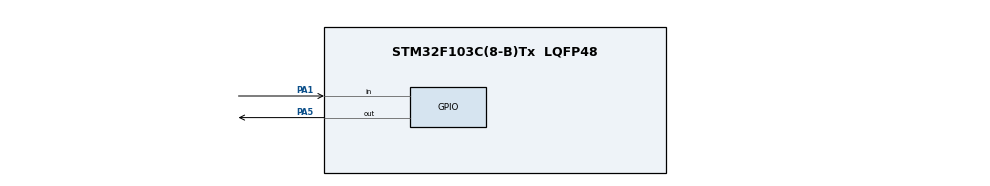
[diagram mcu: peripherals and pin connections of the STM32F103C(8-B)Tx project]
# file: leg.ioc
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Mcu.Family=STM32F1
Mcu.Name=STM32F103C(8-B)Tx
Mcu.Package=LQFP48
NVIC.PriorityGroup=NVIC_PRIORITYGROUP_4
PA1.GPIO_PuPd=GPIO_PULLUP
PA1.Signal=GPIO_Input
PA11.Signal=S_TIM1_CH4
PA13.Mode=JTAG_4_pins
PA13.Signal=SYS_JTMS-SWDIO
PA14.Mode=JTAG_4_pins
PA14.Signal=SYS_JTCK-SWCLK
PA15.Mode=JTAG_4_pins
PA15.Signal=SYS_JTDI
PA5.GPIO_Speed=GPIO_SPEED_FREQ_MEDIUM
PA5.Signal=GPIO_Output
PA5.Stacked=true
PB3.Mode=JTAG_4_pins
PB3.Signal=SYS_JTDO-TRACESWO
PD0-OSC_IN.Mode=HSE-External-Oscillator
PD0-OSC_IN.Signal=RCC_OSC_IN
PD1-OSC_OUT.Mode=HSE-External-Oscillator
PD1-OSC_OUT.Signal=RCC_OSC_OUT
ProjectManager.HeapSize=0x200
ProjectManager.StackSize=0x400
ProjectManager.TargetToolchain=STM32CubeIDE
RCC.AHBFreq_Value=72000000
RCC.APB1CLKDivider=RCC_HCLK_DIV2
RCC.APB1Freq_Value=36000000
RCC.APB1TimFreq_Value=72000000
RCC.APB2Freq_Value=72000000
RCC.APB2TimFreq_Value=72000000
RCC.HCLKFreq_Value=72000000
RCC.PLLMUL=RCC_PLL_MUL9
RCC.PLLSourceVirtual=RCC_PLLSOURCE_HSE
RCC.SYSCLKFreq_VALUE=72000000
RCC.SYSCLKSource=RCC_SYSCLKSOURCE_PLLCLK
RCC.USBFreq_Value=72000000
SH.S_TIM1_CH4.0=TIM1_CH4
board=custom

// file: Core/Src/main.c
/* USER CODE BEGIN Header */

/* USER CODE BEGIN PV */
#define LED4_ON() LL_GPIO_SetOutputPin(GPIOA, LL_GPIO_PIN_5)
#define LED4_OFF() LL_GPIO_ResetOutputPin(GPIOA, LL_GPIO_PIN_5)
#define TIM_CCER_CC3NE                                           ((uint16_t)0x0400)
#define TIMER_PRESCALER                                          720
#define EXT_TIM_PULSE                                            150
#define TIM_PULSE                                                50
//#define LED8_ON() LL_GPIO_SetOutputPin(GPIOB, LL_GPIO_PIN_1)
//#define LED8_OFF() LL_GPIO_ResetOutputPin(GPIOB, LL_GPIO_PIN_1)
/**
  ******************************************************************************
  * @file           : main.c
  * @brief          : Main program body
  ******************************************************************************
  * @attention
  *
  * <h2><center>&copy; Copyright (c) 2021 STMicroelectronics.
  * All rights reserved.</center></h2>
  *
  * This software component is licensed by ST under BSD 3-Clause license,
  * the "License"; You may not use this file except in compliance with the
  * License. You may obtain a copy of the License at:
  *                        opensource.org/licenses/BSD-3-Clause
  *
  ******************************************************************************
  */
/* USER CODE END Header */
#include "main.h"

/* USER CODE BEGIN PV */
#define LED4_ON() LL_GPIO_SetOutputPin(GPIOA, LL_GPIO_PIN_5)
#define LED4_OFF() LL_GPIO_ResetOutputPin(GPIOA, LL_GPIO_PIN_5)
//#define LED8_ON() LL_GPIO_SetOutputPin(GPIOB, LL_GPIO_PIN_1)
//#define LED8_OFF() LL_GPIO_ResetOutputPin(GPIOB, LL_GPIO_PIN_1)
/**
  ******************************************************************************
  * @file           : main.c
  * @brief          : Main program body
  ******************************************************************************
  * @attention
  *
  * <h2><center>&copy; Copyright (c) 2021 STMicroelectronics.
  * All rights reserved.</center></h2>
  *
  * This software component is licensed by ST under BSD 3-Clause license,
  * the "License"; You may not use this file except in compliance with the
  * License. You may obtain a copy of the License at:
  *                        opensource.org/licenses/BSD-3-Clause
  *
  ******************************************************************************
  */
/* USER CODE END Header */
/* Includes ------------------------------------------------------------------*/
#include "main.h"

/* Private includes ----------------------------------------------------------*/
/* USER CODE BEGIN Includes */

/* USER CODE END Includes */

/* Private typedef -----------------------------------------------------------*/
/* USER CODE BEGIN PTD */

/* USER CODE END PTD */

/* Private define ------------------------------------------------------------*/
/* USER CODE BEGIN PD */
/* USER CODE END PD */

/* Private macro -------------------------------------------------------------*/
/* USER CODE BEGIN PM */

/* USER CODE END PM */

/* Private variables ---------------------------------------------------------*/

/* USER CODE BEGIN PV */
#define LED4_ON() LL_GPIO_SetOutputPin(GPIOA, LL_GPIO_PIN_5)
#define LED4_OFF() LL_GPIO_ResetOutputPin(GPIOA, LL_GPIO_PIN_5)
//#define LED8_ON() LL_GPIO_SetOutputPin(GPIOB, LL_GPIO_PIN_1)
//#define LED8_OFF() LL_GPIO_ResetOutputPin(GPIOB, LL_GPIO_PIN_1)
/**
  ******************************************************************************
  * @file           : main.c
  * @brief          : Main program body
  ******************************************************************************
  * @attention
  *
  * <h2><center>&copy; Copyright (c) 2021 STMicroelectronics.
  * All rights reserved.</center></h2>
  *
  * This software component is licensed by ST under BSD 3-Clause license,
  * the "License"; You may not use this file except in compliance with the
  * License. You may obtain a copy of the License at:
  *                        opensource.org/licenses/BSD-3-Clause
  *
  ******************************************************************************
  */
/* USER CODE END Header */
/* Includes ------------------------------------------------------------------*/
#include "main.h"

/* Private includes ----------------------------------------------------------*/
/* USER CODE BEGIN Includes */

/* USER CODE END Includes */

/* Private typedef -----------------------------------------------------------*/
/* USER CODE BEGIN PTD */

/* USER CODE END PTD */

/* Private define ------------------------------------------------------------*/
/* USER CODE BEGIN PD */
/* USER CODE END PD */

/* Private macro -------------------------------------------------------------*/
/* USER CODE BEGIN PM */

/* USER CODE END PM */

/* Private variables ---------------------------------------------------------*/

/* USER CODE BEGIN PV */

/* USER CODE END PV */

void SystemClock_Config(void);
static void MX_GPIO_Init(void);

int main(void)
{

  /* MCU Configuration--------------------------------------------------------*/

  /* Reset of all peripherals, Initializes the Flash interface and the Systick. */

  LL_APB2_GRP1_EnableClock(LL_APB2_GRP1_PERIPH_AFIO);
  LL_APB1_GRP1_EnableClock(LL_APB1_GRP1_PERIPH_PWR);

  NVIC_SetPriorityGrouping(NVIC_PRIORITYGROUP_4);

  /* System interrupt init*/
  /* SysTick_IRQn interrupt configuration */
  NVIC_SetPriority(SysTick_IRQn, NVIC_EncodePriority(NVIC_GetPriorityGrouping(),15, 0));

  /** NONJTRST: Full SWJ (JTAG-DP + SW-DP) but without NJTRST
  */
  LL_GPIO_AF_Remap_SWJ_NONJTRST();

  /* Configure the system clock */
  SystemClock_Config();

  /* Initialize all configured peripherals */
  MX_GPIO_Init();
  /* USER CODE BEGIN 2 */
  uint16_t previousState;
  GPIO_InitTypeDef port;
  TIM_TimeBaseInitTypeDef timer;
  TIM_OCInitTypeDef timerPWM;
  uint16_t buttonPreviousState;

  /* USER CODE END 2 */

  /* Infinite loop */
  while (1)
  {

    /* USER CODE BEGIN 3 */
	  LED4_OFF();
	  LL_mDelay(100);
	  LED4_ON();
	  LL_mDelay(200);
	  TIM_OCStructInit(&timerPWM);
	  timerPWM.TIM_Pulse = 50;
	  timerPWM.TIM_OCMode = TIM_OCMode_PWM1;
	  timerPWM.TIM_OutputState = TIM_OutputState_Enable;
	  TIM_OC1Init(TIM4, &timerPWM);
  }
  /* USER CODE END 3 */
}

void SystemClock_Config(void)
{
  LL_FLASH_SetLatency(LL_FLASH_LATENCY_2);
  while(LL_FLASH_GetLatency()!= LL_FLASH_LATENCY_2)
  {
  }
  LL_RCC_HSE_Enable();

   /* Wait till HSE is ready */
  while(LL_RCC_HSE_IsReady() != 1)
  {

  }
  LL_RCC_PLL_ConfigDomain_SYS(LL_RCC_PLLSOURCE_HSE_DIV_1, LL_RCC_PLL_MUL_9);
  LL_RCC_PLL_Enable();

   /* Wait till PLL is ready */
  while(LL_RCC_PLL_IsReady() != 1)
  {

  }
  LL_RCC_SetAHBPrescaler(LL_RCC_SYSCLK_DIV_1);
  LL_RCC_SetAPB1Prescaler(LL_RCC_APB1_DIV_2);
  LL_RCC_SetAPB2Prescaler(LL_RCC_APB2_DIV_1);
  LL_RCC_SetSysClkSource(LL_RCC_SYS_CLKSOURCE_PLL);

   /* Wait till System clock is ready */
  while(LL_RCC_GetSysClkSource() != LL_RCC_SYS_CLKSOURCE_STATUS_PLL)
  {

  }
  LL_Init1msTick(72000000);
  LL_SetSystemCoreClock(72000000);
}

static void MX_GPIO_Init(void)
{
  LL_GPIO_InitTypeDef GPIO_InitStruct = {0};

  /* GPIO Ports Clock Enable */
  LL_APB2_GRP1_EnableClock(LL_APB2_GRP1_PERIPH_GPIOD);
  LL_APB2_GRP1_EnableClock(LL_APB2_GRP1_PERIPH_GPIOA);
  LL_APB2_GRP1_EnableClock(LL_APB2_GRP1_PERIPH_GPIOB);

  /**/
  LL_GPIO_ResetOutputPin(GPIOA, LL_GPIO_PIN_5);

  /**/
  GPIO_InitStruct.Pin = LL_GPIO_PIN_1;
  GPIO_InitStruct.Mode = LL_GPIO_MODE_INPUT;
  GPIO_InitStruct.Pull = LL_GPIO_PULL_UP;
  LL_GPIO_Init(GPIOA, &GPIO_InitStruct);

  /**/
  GPIO_InitStruct.Pin = LL_GPIO_PIN_5;
  GPIO_InitStruct.Mode = LL_GPIO_MODE_OUTPUT;
  GPIO_InitStruct.Speed = LL_GPIO_SPEED_FREQ_MEDIUM;
  GPIO_InitStruct.OutputType = LL_GPIO_OUTPUT_PUSHPULL;
  LL_GPIO_Init(GPIOA, &GPIO_InitStruct);

}

void Error_Handler(void)
{
  __disable_irq();
  while (1)
  {
  }
}

/************************ (C) COPYRIGHT STMicroelectronics *****END OF FILE****/
